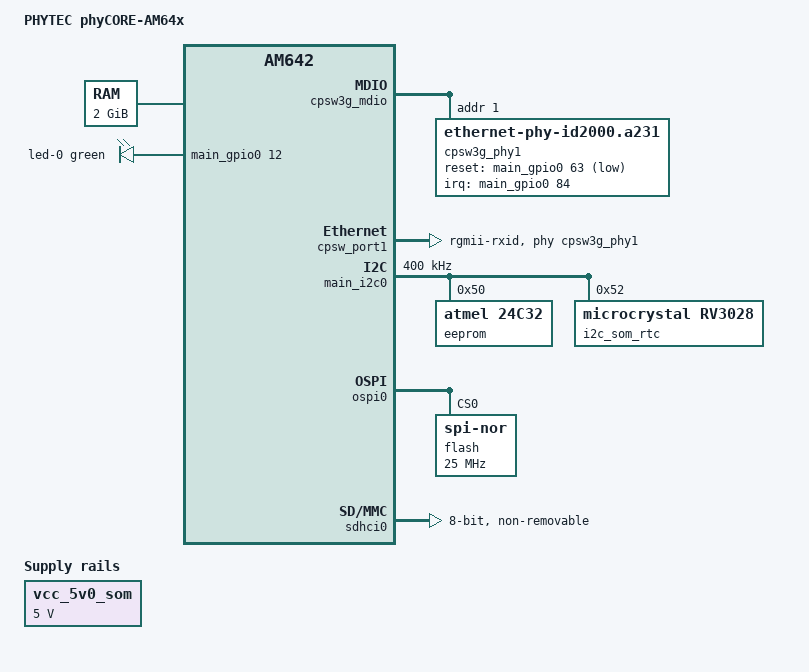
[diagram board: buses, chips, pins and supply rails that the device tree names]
#include <dt-bindings/gpio/gpio.h>
#include <dt-bindings/leds/common.h>
#include <dt-bindings/net/ti-dp83867.h>
/ {
	model = "PHYTEC phyCORE-AM64x";
	compatible = "phytec,am64-phycore-som", "ti,am642";
	aliases {
		ethernet0 = &cpsw_port1;
		mmc0 = &sdhci0;
		rtc0 = &i2c_som_rtc;
	};
	memory@80000000 {
		device_type = "memory";
		reg = <0x00000000 0x80000000 0x00000000 0x80000000>;
	};
	reserved-memory {
		#address-cells = <2>;
		#size-cells = <2>;
		ranges;
		secure_ddr: optee@9e800000 {
			reg = <0x00 0x9e800000 0x00 0x01800000>;  
			alignment = <0x1000>;
			no-map;
		};
	};
	leds {
		compatible = "gpio-leds";
		pinctrl-names = "default";
		pinctrl-0 = <&leds_pins_default>;
		led-0 {
			color = <LED_COLOR_ID_GREEN>;
			gpios = <&main_gpio0 12 GPIO_ACTIVE_HIGH>;
			linux,default-trigger = "heartbeat";
			function = LED_FUNCTION_HEARTBEAT;
		};
	};
	vcc_5v0_som: regulator-vcc-5v0-som {
		compatible = "regulator-fixed";
		regulator-name = "VCC_5V0_SOM";
		regulator-min-microvolt = <5000000>;
		regulator-max-microvolt = <5000000>;
		regulator-always-on;
		regulator-boot-on;
	};
};
&main_pmx0 {
	cpsw_mdio_pins_default: cpsw-mdio-default-pins {
		pinctrl-single,pins = <
			AM64X_IOPAD(0x01f8, PIN_INPUT, 4)	 
			AM64X_IOPAD(0x01fc, PIN_OUTPUT, 4)	 
			AM64X_IOPAD(0x0100, PIN_OUTPUT, 7)	 
		>;
	};
	cpsw_rgmii1_pins_default: cpsw-rgmii1-default-pins {
		pinctrl-single,pins = <
			AM64X_IOPAD(0x0184, PIN_INPUT, 4)	 
			AM64X_IOPAD(0x0188, PIN_INPUT, 4)	 
			AM64X_IOPAD(0x00dc, PIN_OUTPUT, 4)	 
			AM64X_IOPAD(0x00e0, PIN_OUTPUT, 4)	 
			AM64X_IOPAD(0x01cc, PIN_INPUT, 4)	 
			AM64X_IOPAD(0x0124, PIN_OUTPUT, 4)	 
			AM64X_IOPAD(0x01d4, PIN_INPUT, 4)	 
			AM64X_IOPAD(0x012c, PIN_OUTPUT, 4)	 
			AM64X_IOPAD(0x01d8, PIN_INPUT, 4)	 
			AM64X_IOPAD(0x0130, PIN_OUTPUT, 4)	 
			AM64X_IOPAD(0x01f4, PIN_INPUT, 4)	 
			AM64X_IOPAD(0x014c, PIN_OUTPUT, 4)	 
			AM64X_IOPAD(0x0154, PIN_INPUT, 7)	 
		>;
	};
	eeprom_wp_pins_default: eeprom-wp-default-pins {
		pinctrl-single,pins = <
			AM64X_IOPAD(0x0208, PIN_OUTPUT, 7)	 
		>;
	};
	leds_pins_default: leds-default-pins {
		pinctrl-single,pins = <
			AM64X_IOPAD(0x0030, PIN_OUTPUT, 7)	 
		>;
	};
	main_i2c0_pins_default: main-i2c0-default-pins {
		pinctrl-single,pins = <
			AM64X_IOPAD(0x0260, PIN_INPUT, 0)	 
			AM64X_IOPAD(0x0264, PIN_INPUT, 0)	 
		>;
	};
	ospi0_pins_default: ospi0-default-pins {
		pinctrl-single,pins = <
			AM64X_IOPAD(0x0000, PIN_OUTPUT, 0)	 
			AM64X_IOPAD(0x0008, PIN_INPUT, 0)	 
			AM64X_IOPAD(0x000c, PIN_INPUT, 0)	 
			AM64X_IOPAD(0x0010, PIN_INPUT, 0)	 
			AM64X_IOPAD(0x0014, PIN_INPUT, 0)	 
			AM64X_IOPAD(0x0018, PIN_INPUT, 0)	 
			AM64X_IOPAD(0x001c, PIN_INPUT, 0)	 
			AM64X_IOPAD(0x0020, PIN_INPUT, 0)	 
			AM64X_IOPAD(0x0024, PIN_INPUT, 0)	 
			AM64X_IOPAD(0x0028, PIN_INPUT, 0)	 
			AM64X_IOPAD(0x002c, PIN_OUTPUT, 0)	 
		>;
	};
};
&cpsw3g {
	pinctrl-names = "default";
	pinctrl-0 = <&cpsw_rgmii1_pins_default>;
};
&cpsw3g_mdio {
	status = "okay";
	pinctrl-names = "default";
	pinctrl-0 = <&cpsw_mdio_pins_default>;
	cpsw3g_phy1: ethernet-phy@1 {
		compatible = "ethernet-phy-id2000.a231", "ethernet-phy-ieee802.3-c22";
		reg = <1>;
		interrupt-parent = <&main_gpio0>;
		interrupts = <84 IRQ_TYPE_EDGE_FALLING>;
		ti,rx-internal-delay = <DP83867_RGMIIDCTL_2_00_NS>;
		ti,fifo-depth = <DP83867_PHYCR_FIFO_DEPTH_4_B_NIB>;
		reset-gpios = <&main_gpio0 63 GPIO_ACTIVE_LOW>;
		reset-assert-us = <1000>;
		reset-deassert-us = <1000>;
	};
};
&cpsw_port1 {
	phy-mode = "rgmii-rxid";
	phy-handle = <&cpsw3g_phy1>;
};
&cpsw_port2 {
	status = "disabled";
};
&main_i2c0 {
	status = "okay";
	pinctrl-names = "default";
	pinctrl-0 = <&main_i2c0_pins_default>;
	clock-frequency = <400000>;
	eeprom@50 {
		compatible = "atmel,24c32";
		pinctrl-names = "default";
		pinctrl-0 = <&eeprom_wp_pins_default>;
		pagesize = <32>;
		reg = <0x50>;
	};
	i2c_som_rtc: rtc@52 {
		compatible = "microcrystal,rv3028";
		reg = <0x52>;
	};
};
&ospi0 {
	status = "okay";
	pinctrl-names = "default";
	pinctrl-0 = <&ospi0_pins_default>;
	flash@0 {
		compatible = "jedec,spi-nor";
		reg = <0x0>;
		spi-tx-bus-width = <8>;
		spi-rx-bus-width = <8>;
		spi-max-frequency = <25000000>;
		cdns,tshsl-ns = <60>;
		cdns,tsd2d-ns = <60>;
		cdns,tchsh-ns = <60>;
		cdns,tslch-ns = <60>;
		cdns,read-delay = <0>;
	};
};
&sdhci0 {
	bus-width = <8>;
	non-removable;
	ti,driver-strength-ohm = <50>;
	disable-wp;
	keep-power-in-suspend;
};
